AUTOSAR XML (schema 4-0-3)
package /ComponentTypes
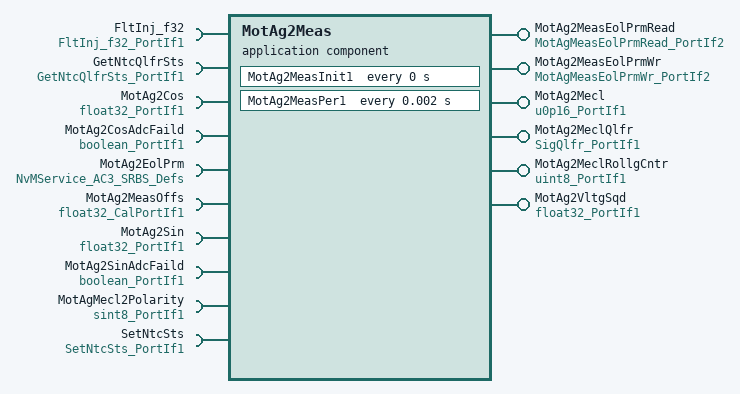
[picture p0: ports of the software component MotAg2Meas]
  application sw component type MotAg2Meas
    6 x provide port:
      MotAg2MeasEolPrmRead: server-com-spec{operation=Oper, queue-length=1}, provided-interface=MotAgMeasEolPrmRead_PortIf2
      MotAg2MeasEolPrmWr: server-com-spec{operation=Oper, queue-length=1}, provided-interface=MotAgMeasEolPrmWr_PortIf2
      MotAg2Mecl: nonqueued-sender-com-spec{data-element=Val, init-value=0}, provided-interface=u0p16_PortIf1
      MotAg2MeclQlfr: nonqueued-sender-com-spec{data-element=Val, init-value=0}, provided-interface=SigQlfr_PortIf1
      MotAg2MeclRollgCntr: nonqueued-sender-com-spec{data-element=Val, init-value=0}, provided-interface=uint8_PortIf1
      MotAg2VltgSqd: nonqueued-sender-com-spec{data-element=Val, init-value=1.755625}, provided-interface=float32_PortIf1
    10 x require port:
      FltInj_f32: client-com-spec=Oper, required-interface=FltInj_f32_PortIf1
      GetNtcQlfrSts: client-com-spec=Oper, required-interface=GetNtcQlfrSts_PortIf1
      MotAg2Cos: nonqueued-receiver-com-spec{data-element=Val, filter=data-filter-type=ALWAYS, init-value=0}, required-interface=float32_PortIf1
      MotAg2CosAdcFaild: nonqueued-receiver-com-spec{data-element=Logl, filter=data-filter-type=ALWAYS, init-value=0}, required-interface=boolean_PortIf1
      MotAg2EolPrm: required-com-specs=[EraseBlock, GetErrorStatus, InvalidateNvBlock, ReadBlock, RestoreBlockDefaults, SetRamBlockStatus, WriteBlock], required-interface=NvMService_AC3_SRBS_Defs
      MotAg2MeasOffs: parameter-require-com-spec{init-value=0, parameter=Val}, required-interface=float32_CalPortIf1
      MotAg2Sin: nonqueued-receiver-com-spec{data-element=Val, filter=data-filter-type=ALWAYS, init-value=0}, required-interface=float32_PortIf1
      MotAg2SinAdcFaild: nonqueued-receiver-com-spec{data-element=Logl, filter=data-filter-type=ALWAYS, init-value=0}, required-interface=boolean_PortIf1
      MotAgMecl2Polarity: nonqueued-receiver-com-spec{data-element=Val, filter=data-filter-type=ALWAYS, init-value=1}, required-interface=sint8_PortIf1
      SetNtcSts: client-com-spec=Oper, required-interface=SetNtcSts_PortIf1
    behavior MotAg2Meas_InternalBehavior
      ar-typed-per-instance-memorys:
        data MotAg2EolPrm: sw-calibration-access=READ-ONLY, type=MotAgMeasEolPrmRec1
        data MotAg2MeclPrev: sw-calibration-access=READ-ONLY, type=float32
        data MotAg2MeclRollgCntrPrev: sw-calibration-access=READ-ONLY, type=uint8
      operation invoked event OIT_MotAg2MeasEolPrmRead_Oper_MotAg2MeasEolPrmRead_Oper: start-on-event=MotAg2MeasEolPrmRead_Oper, operation=MotAg2MeasEolPrmRead.Oper
      operation invoked event OIT_MotAg2MeasEolPrmWr_Oper_MotAg2MeasEolPrmWr_Oper: start-on-event=MotAg2MeasEolPrmWr_Oper, operation=MotAg2MeasEolPrmWr.Oper
      timing event MotAg2Meas_InitEvent: start-on-event=MotAg2MeasInit1, period=0
      timing event TMT_MotAg2MeasPer1: start-on-event=MotAg2MeasPer1, period=0.002
      4 x runnable:
        MotAg2MeasEolPrmRead_Oper
        MotAg2MeasEolPrmWr_Oper
          sync call SC_MtrAg2EolPrm_SetRamBlockStatus: operation=MotAg2EolPrm.SetRamBlockStatus, timeout=0
        MotAg2MeasInit1
          sync call SC_MtrAg2EolPrm_GetErrorStatus: operation=MotAg2EolPrm.GetErrorStatus, timeout=0
        MotAg2MeasPer1
          data-receive-point-by-arguments:
            5 x access:
              REC_MotAg2Cos_Val: accessed-variable=MotAg2Cos.Val
              REC_MotAg2CosAdcFaild_Logl: accessed-variable=MotAg2CosAdcFaild.Logl
              REC_MotAg2Sin_Val: accessed-variable=MotAg2Sin.Val
              REC_MotAg2SinAdcFaild_Logl: accessed-variable=MotAg2SinAdcFaild.Logl
              REC_MotAgMecl2Polarity_Val: accessed-variable=MotAgMecl2Polarity.Val
          data-send-points:
            4 x access:
              SEND_MotAg2Mecl_Val: accessed-variable=MotAg2Mecl.Val
              SEND_MotAg2MeclQlfr_Val: accessed-variable=MotAg2MeclQlfr.Val
              SEND_MotAg2MeclRollgCntr_Val: accessed-variable=MotAg2MeclRollgCntr.Val
              SEND_MotAg2VltgSqd_Val: accessed-variable=MotAg2VltgSqd.Val
          sync call SC_FltInj_f32_Oper: operation=FltInj_f32.Oper, timeout=0
          sync call SC_GetNtcQlfrSts_Oper: operation=GetNtcQlfrSts.Oper, timeout=0
          sync call SC_SetNtcSts_Oper: operation=SetNtcSts.Oper, timeout=0
      swc service dependency NvmMotAg2EolPrm: assigned-ports=role-based-port-assignment={port-prototype=MotAg2EolPrm, role=NvMService_AC3_SRBS_Defs}
        assigned-datas:
          role=ramBlock, used-data-element=MotAg2EolPrm
          role=defaultValue, used-parameter-element=MotAg2EolPrmDft
        service-needs:
          nv block needs NvmMotAg2EolPrm: n-data-sets=0, readonly=false, reliability=ERROR-DETECTION, resistant-to-changed-sw=true, restore-at-start=true, store-at-shutdown=true, write-only-once=false, writing-frequency=0, writing-priority=LOW
      shared-parameters:
        parameter data prototype MotAg2EolPrmDft: sw-calibration-access=READ-WRITE, type=MotAgMeasEolPrmRec1, init-value=fields=[SinOffs:2.5, CosOffs:2.5, SinAmpRecpr:1, CosAmpRecpr:1, SinDelta:0]
  swc implementation MotAg2Meas_Implementation: behavior=MotAg2Meas_InternalBehavior
    code-descriptors:
      code Default: artifact-descriptors=autosar-engineering-object={short-label=Default, category=SWSRC}
